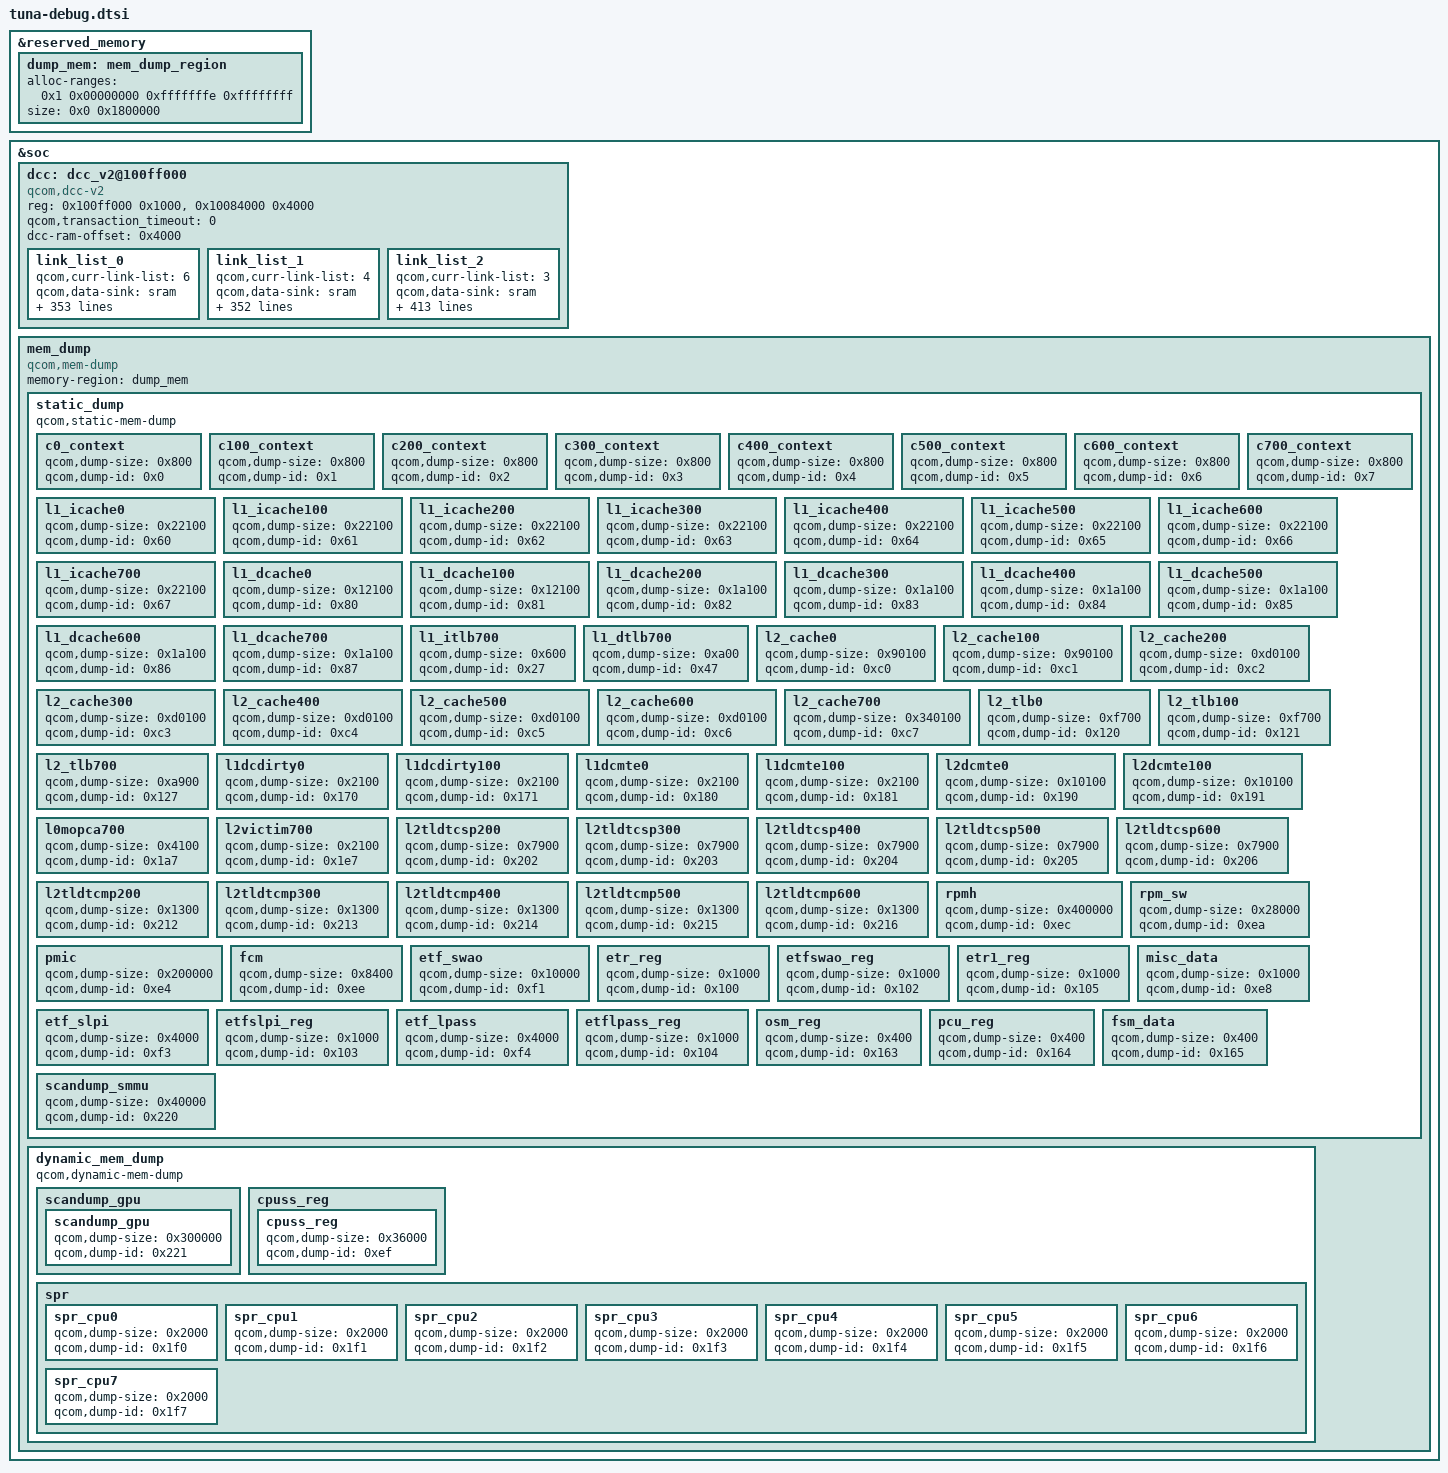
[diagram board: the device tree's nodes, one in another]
// SPDX-License-Identifier: BSD-3-Clause
/*
 * Copyright (c) 2023-2025 Qualcomm Innovation Center, Inc. All rights reserved.
 */

#include <dt-bindings/soc/qcom,dcc_v2.h>

&reserved_memory {
	#address-cells = <2>;
	#size-cells = <2>;
	ranges;

	dump_mem: mem_dump_region {
		alloc-ranges = <0x1 0x00000000 0xfffffffe 0xffffffff>;
		size = <0x0 0x1800000>;
	};
};

&soc {
	dcc: dcc_v2@100ff000 {
		compatible = "qcom,dcc-v2";
		reg = <0x100ff000 0x1000>,
		      <0x10084000 0x4000>;

		qcom,transaction_timeout = <0>;

		reg-names = "dcc-base", "dcc-ram-base";
		dcc-ram-offset = <0x4000>;

		link_list_0 {
			qcom,curr-link-list = <6>;
			qcom,data-sink = "sram";
			qcom,ap-qad-override;
			qcom,link-list = <DCC_READ 0x17421000 2 0>,
				<DCC_READ 0x1740003c 1 0>,
				<DCC_READ 0x17600238 1 0>,
				<DCC_READ 0x17600240 11 0>,
				<DCC_READ 0x17600530 1 0>,
				<DCC_READ 0x1760051c 1 0>,
				<DCC_READ 0x17600524 1 0>,
				<DCC_READ 0x1760052c 1 0>,
				<DCC_READ 0x17600518 1 0>,
				<DCC_READ 0x17600520 1 0>,
				<DCC_READ 0x17600528 1 0>,
				<DCC_READ 0x17600404 3 0>,
				<DCC_READ 0x1760041c 3 0>,
				<DCC_READ 0x17600434 1 0>,
				<DCC_READ 0x1760043c 1 0>,
				<DCC_READ 0x17600440 1 0>,
				<DCC_READ 0x17400438 1 0>,
				<DCC_READ 0x17600044 1 0>,
				<DCC_READ 0x17600500 1 0>,
				<DCC_READ 0x17600504 5 0>,
				<DCC_READ 0x17900908 1 0>,
				<DCC_READ 0x17900c18 1 0>,
				<DCC_READ 0x17901908 1 0>,
				<DCC_READ 0x17901c18 1 0>,
				<DCC_READ 0x17902908 1 0>,
				<DCC_READ 0x17902c18 1 0>,
				<DCC_READ 0x17b90810 1 0>,
				<DCC_READ 0x17b90c50 1 0>,
				<DCC_READ 0x17b90814 1 0>,
				<DCC_READ 0x17b90c54 1 0>,
				<DCC_READ 0x17b90818 1 0>,
				<DCC_READ 0x17b90c58 1 0>,
				<DCC_READ 0x17b93a04 2 0>,
				<DCC_READ 0x17b94810 1 0>,
				<DCC_READ 0x17b94814 1 0>,
				<DCC_READ 0x17b94818 1 0>,
				<DCC_READ 0x17b97a04 1 0>,
				<DCC_READ 0x17ba0810 1 0>,
				<DCC_READ 0x17ba0c50 1 0>,
				<DCC_READ 0x17ba0814 1 0>,
				<DCC_READ 0x17ba0c54 1 0>,
				<DCC_READ 0x17ba0818 1 0>,
				<DCC_READ 0x17ba0c58 1 0>,
				<DCC_READ 0x17ba3a04 2 0>,
				<DCC_READ 0x17b93000 80 0>,
				<DCC_READ 0x17b97000 40 0>,
				<DCC_READ 0x17ba3000 80 0>,
				<DCC_READ 0x0c201244 1 0>,
				<DCC_READ 0x0c202244 1 0>,
				<DCC_READ 0x17b02000 1 0>,
				<DCC_READ 0x17b00000 1 0>,
				<DCC_READ 0x17d98024 1 0>,
				<DCC_READ 0x13822000 1 0>,
				<DCC_READ 0x221c20a4 1 0>,
				<DCC_READ 0x01fc8000 1 0>,
				<DCC_READ 0x17400038 1 0>,
				<DCC_READ 0x17d91020 1 0>,
				<DCC_READ 0x17d92020 1 0>,
				<DCC_READ 0x17d93020 1 0>,
				<DCC_READ 0x17d94020 1 0>,
				<DCC_READ 0x17d90020 1 0>,
				<DCC_READ 0x17d9134c 1 0>,
				<DCC_READ 0x17d9234c 1 0>,
				<DCC_READ 0x17d9334c 1 0>,
				<DCC_READ 0x17d9434c 1 0>,
				<DCC_READ 0x17d9034c 1 0>,
				<DCC_READ 0x17d91300 1 0>,
				<DCC_READ 0x17d92300 1 0>,
				<DCC_READ 0x17d93300 1 0>,
				<DCC_READ 0x17d94300 1 0>,
				<DCC_READ 0x17d90300 1 0>,
				<DCC_READ 0x24100008 1 >,
				<DCC_READ 0x24100010 1 >,
				<DCC_READ 0x24100018 1 >,
				<DCC_READ 0x24100020 6 0>,
				<DCC_READ 0x24102008 1 >,
				<DCC_LOOP 0x2 0 0>,
				<DCC_READ 0x24102010 2 0>,
				<DCC_LOOP 0x1 0 0>,
				<DCC_READ 0x24102018 1 0>,
				<DCC_READ 0x24102080 3 0>,
				<DCC_LOOP 0x3 0 0>,
				<DCC_READ 0x24102090 2 0>,
				<DCC_LOOP 0x1 0 0>,
				<DCC_READ 0x24102098 1 0>,
				<DCC_READ 0x24131010 1 >,
				<DCC_READ 0x24133010 1 >,
				<DCC_READ 0x24135010 1 >,
				<DCC_READ 0x24137010 1 >,
				<DCC_READ 0x24138010 1 >,
				<DCC_READ 0x24180008 1 >,
				<DCC_READ 0x24180010 1 >,
				<DCC_READ 0x24180018 1 >,
				<DCC_READ 0x24180020 6 0>,
				<DCC_READ 0x24182000 3 0>,
				<DCC_LOOP 0x2 0 0>,
				<DCC_READ 0x24182010 2 0>,
				<DCC_LOOP 0x1 0 0>,
				<DCC_READ 0x24182018 1 0>,
				<DCC_READ 0x24182080 3 0>,
				<DCC_LOOP 0x3 0 0>,
				<DCC_READ 0x24182090 2 0>,
				<DCC_LOOP 0x1 0 0>,
				<DCC_READ 0x24182098 1 0>,
				<DCC_READ 0x241b1010 1 >,
				<DCC_READ 0x241b3010 1 >,
				<DCC_READ 0x241b5010 1 >,
				<DCC_READ 0x241b7010 1 >,
				<DCC_READ 0x241b8010 1 >,
				<DCC_READ 0x24200008 1 >,
				<DCC_READ 0x24200010 1 >,
				<DCC_READ 0x24200018 1 >,
				<DCC_READ 0x24200020 6 0>,
				<DCC_READ 0x24200408 1 >,
				<DCC_READ 0x24200410 1 >,
				<DCC_READ 0x24200418 1 >,
				<DCC_READ 0x24200420 6 0>,
				<DCC_READ 0x24201040 1 >,
				<DCC_READ 0x24201048 1 >,
				<DCC_READ 0x24204000 3 0>,
				<DCC_LOOP 0x3 0 0>,
				<DCC_READ 0x24204010 2 0>,
				<DCC_LOOP 0x1 0 0>,
				<DCC_READ 0x24204018 1 0>,
				<DCC_READ 0x24204080 3 0>,
				<DCC_LOOP 0x11 0 0>,
				<DCC_READ 0x24204090 2 0>,
				<DCC_LOOP 0x1 0 0>,
				<DCC_READ 0x24204098 1 0>,
				<DCC_READ 0x24209040 4 0>,
				<DCC_READ 0x2423a010 1 >,
				<DCC_READ 0x2423c010 1 >,
				<DCC_READ 0x2423e010 1 >,
				<DCC_READ 0x24240010 1 >,
				<DCC_READ 0x24242010 1 >,
				<DCC_READ 0x24244010 1 >,
				<DCC_READ 0x24246010 1 >,
				<DCC_READ 0x24248010 1 >,
				<DCC_READ 0x2424a010 1 >,
				<DCC_READ 0x2424b010 1 >,
				<DCC_READ 0x2424d010 1 >,
				<DCC_READ 0x24101010 1 >,
				<DCC_WRITE 0x24101028 0x2 0>,
				<DCC_LOOP 0x40 0 0>,
				<DCC_READ 0x24101030 2 0>,
				<DCC_READ 0x24101030 2 0>,
				<DCC_READ 0x24101030 2 0>,
				<DCC_READ 0x24101030 2 0>,
				<DCC_LOOP 0x1 0 0>,
				<DCC_WRITE 0x24101028 0x1 0>,
				<DCC_READ 0x24101038 1 0>,
				<DCC_READ 0x24181010 1 >,
				<DCC_WRITE 0x24181028 0x2 0>,
				<DCC_LOOP 0x40 0 0>,
				<DCC_READ 0x24181030 2 0>,
				<DCC_READ 0x24181030 2 0>,
				<DCC_READ 0x24181030 2 0>,
				<DCC_READ 0x24181030 2 0>,
				<DCC_LOOP 0x1 0 0>,
				<DCC_WRITE 0x24181028 0x1 0>,
				<DCC_READ 0x24181038 1 0>,
				<DCC_READ 0x24203010 1 >,
				<DCC_WRITE 0x24203028 0x2 0>,
				<DCC_LOOP 0x10 0 0>,
				<DCC_READ 0x24203030 2 0>,
				<DCC_READ 0x24203030 2 0>,
				<DCC_READ 0x24203030 2 0>,
				<DCC_READ 0x24203030 2 0>,
				<DCC_LOOP 0x1 0 0>,
				<DCC_WRITE 0x24203028 0x1 0>,
				<DCC_READ 0x24203038 1 0>,
				<DCC_READ 0x24203410 1 >,
				<DCC_WRITE 0x24203428 0x2 0>,
				<DCC_LOOP 0x10 0 0>,
				<DCC_READ 0x24203430 2 0>,
				<DCC_READ 0x24203430 2 0>,
				<DCC_READ 0x24203430 2 0>,
				<DCC_READ 0x24203430 2 0>,
				<DCC_LOOP 0x1 0 0>,
				<DCC_WRITE 0x24203428 0x1 0>,
				<DCC_READ 0x24203438 1 0>,
				<DCC_READ 0x17800010 1 >,
				<DCC_READ 0x17800024 1 >,
				<DCC_READ 0x17800038 6 0>,
				<DCC_READ 0x17800058 4 0>,
				<DCC_READ 0x1780006c 1 >,
				<DCC_READ 0x178000f0 2 0>,
				<DCC_READ 0x17810010 1 >,
				<DCC_READ 0x17810024 1 >,
				<DCC_READ 0x17810038 6 0>,
				<DCC_READ 0x17810058 4 0>,
				<DCC_READ 0x1781006c 1 >,
				<DCC_READ 0x178100f0 2 0>,
				<DCC_READ 0x17820010 1 >,
				<DCC_READ 0x17820024 1 >,
				<DCC_READ 0x17820038 6 0>,
				<DCC_READ 0x17820058 4 0>,
				<DCC_READ 0x178200f0 2 0>,
				<DCC_READ 0x17830010 1 >,
				<DCC_READ 0x17830024 1 >,
				<DCC_READ 0x17830038 6 0>,
				<DCC_READ 0x17830058 4 0>,
				<DCC_READ 0x178300f0 2 0>,
				<DCC_READ 0x17840010 1 >,
				<DCC_READ 0x17840024 1 >,
				<DCC_READ 0x17840038 6 0>,
				<DCC_READ 0x17840058 4 0>,
				<DCC_READ 0x178400f0 2 0>,
				<DCC_READ 0x17850010 1 >,
				<DCC_READ 0x17850024 1 >,
				<DCC_READ 0x17850038 6 0>,
				<DCC_READ 0x17850058 4 0>,
				<DCC_READ 0x178500f0 2 0>,
				<DCC_READ 0x17860010 1 >,
				<DCC_READ 0x17860024 1 >,
				<DCC_READ 0x17860038 6 0>,
				<DCC_READ 0x17860058 4 0>,
				<DCC_READ 0x178600f0 2 0>,
				<DCC_READ 0x17870010 1 >,
				<DCC_READ 0x17870024 1 >,
				<DCC_READ 0x17870038 6 0>,
				<DCC_READ 0x17870058 4 0>,
				<DCC_READ 0x178700f0 2 0>,
				<DCC_READ 0x178a0010 1 >,
				<DCC_READ 0x178a0024 1 >,
				<DCC_READ 0x178a0038 6 0>,
				<DCC_READ 0x178a006c 5 0>,
				<DCC_READ 0x178a0084 1 >,
				<DCC_READ 0x178a00f4 5 0>,
				<DCC_READ 0x178a0118 9 0>,
				<DCC_READ 0x178a0158 5 0>,
				<DCC_READ 0x178a0170 2 0>,
				<DCC_READ 0x178a0188 5 0>,
				<DCC_READ 0x178a01ac 6 0>,
				<DCC_READ 0x178a01c8 1 >,
				<DCC_READ 0x178a0290 1 >,
				<DCC_READ 0x178a0204 1 >,
				<DCC_READ 0x178a0244 1 >,
				<DCC_READ 0x17e30000 1 >,
				<DCC_READ 0x17e30008 1 >,
				<DCC_READ 0x17e30010 1 >,
				<DCC_READ 0x17e80000 1 >,
				<DCC_READ 0x17e80008 1 >,
				<DCC_READ 0x17e80010 1 >,
				<DCC_READ 0x17f80000 1 >,
				<DCC_READ 0x17f80008 1 >,
				<DCC_READ 0x17f80010 1 >,
				<DCC_READ 0x18080000 1 >,
				<DCC_READ 0x18080008 1 >,
				<DCC_READ 0x18080010 1 >,
				<DCC_READ 0x18180000 1 >,
				<DCC_READ 0x18180008 1 >,
				<DCC_READ 0x18180010 1 >,
				<DCC_READ 0x18280000 1 >,
				<DCC_READ 0x18280008 1 >,
				<DCC_READ 0x18280010 1 >,
				<DCC_READ 0x18380000 1 >,
				<DCC_READ 0x18380008 1 >,
				<DCC_READ 0x18380010 1 >,
				<DCC_READ 0x18480000 1 >,
				<DCC_READ 0x18480008 1 >,
				<DCC_READ 0x18480010 1 >,
				<DCC_READ 0x18580000 1 >,
				<DCC_READ 0x18580008 1 >,
				<DCC_READ 0x18580010 1 >,
				<DCC_READ 0x17d10200 320 0>,
				<DCC_READ 0x17a00010 1 >,
				<DCC_READ 0x17a00030 1 >,
				<DCC_READ 0x17a00038 1 >,
				<DCC_READ 0x17a00040 1 >,
				<DCC_READ 0x17a00048 1 >,
				<DCC_READ 0x17a00400 1 >,
				<DCC_READ 0x17a10010 1 >,
				<DCC_READ 0x17a10030 1 >,
				<DCC_READ 0x17a10038 1 >,
				<DCC_READ 0x17a10040 1 >,
				<DCC_READ 0x17a10400 1 >,
				<DCC_READ 0x17a20010 1 >,
				<DCC_READ 0x17a20030 1 >,
				<DCC_READ 0x17a20038 1 >,
				<DCC_READ 0x17a20040 1 >,
				<DCC_READ 0x17a20400 1 >,
				<DCC_READ 0x17a30010 1 >,
				<DCC_READ 0x17a30030 1 >,
				<DCC_READ 0x17a30038 1 >,
				<DCC_READ 0x17a30040 1 >,
				<DCC_READ 0x17a30400 1 >,
				<DCC_READ 0x17a10d3c 1 >,
				<DCC_READ 0x17a10d54 1 >,
				<DCC_READ 0x17a10d6c 1 >,
				<DCC_READ 0x17a10d84 1 >,
				<DCC_READ 0x17a10d9c 1 >,
				<DCC_READ 0x17a10db4 1 >,
				<DCC_READ 0x17a10dcc 1 >,
				<DCC_READ 0x17a10de4 1 >,
				<DCC_READ 0x17a10dfc 1 >,
				<DCC_READ 0x17a10e14 1 >,
				<DCC_READ 0x17a10e2c 1 >,
				<DCC_READ 0x17a10e44 1 >,
				<DCC_READ 0x17a10e5c 1 >,
				<DCC_READ 0x17a10e74 1 >,
				<DCC_READ 0x17a10e8c 1 >,
				<DCC_READ 0x17a10ea4 1 >,
				<DCC_READ 0x17a10fdc 1 >,
				<DCC_READ 0x17a10ff4 1 >,
				<DCC_READ 0x17a1100c 1 >,
				<DCC_READ 0x17a11024 1 >,
				<DCC_READ 0x17a1103c 1 >,
				<DCC_READ 0x17a11054 1 >,
				<DCC_READ 0x17a1106c 1 >,
				<DCC_READ 0x17a11084 1 >,
				<DCC_READ 0x17a1109c 1 >,
				<DCC_READ 0x17a110b4 1 >,
				<DCC_READ 0x17a110cc 1 >,
				<DCC_READ 0x17a110e4 1 >,
				<DCC_READ 0x17a110fc 1 >,
				<DCC_READ 0x17a11114 1 >,
				<DCC_READ 0x17a1112c 1 >,
				<DCC_READ 0x17a11144 1 >,
				<DCC_READ 0x17a1127c 1 >,
				<DCC_READ 0x17a11294 1 >,
				<DCC_READ 0x17a112ac 1 >,
				<DCC_READ 0x17a112c4 1 >,
				<DCC_READ 0x17a112dc 1 >,
				<DCC_READ 0x17a112f4 1 >,
				<DCC_READ 0x17a1130c 1 >,
				<DCC_READ 0x17a11324 1 >,
				<DCC_READ 0x17a1133c 1 >,
				<DCC_READ 0x17a11354 1 >,
				<DCC_READ 0x17a1136c 1 >,
				<DCC_READ 0x17a11384 1 >,
				<DCC_READ 0x17a1139c 1 >,
				<DCC_READ 0x17a113b4 1 >,
				<DCC_READ 0x17a113cc 1 >,
				<DCC_READ 0x17a113e4 1 >,
				<DCC_READ 0x17a1151c 1 >,
				<DCC_READ 0x17a11534 1 >,
				<DCC_READ 0x17a1154c 1 >,
				<DCC_READ 0x17a11564 1 >,
				<DCC_READ 0x17a1157c 1 >,
				<DCC_READ 0x17a11594 1 >,
				<DCC_READ 0x17a115ac 1 >,
				<DCC_READ 0x17a115c4 1 >,
				<DCC_READ 0x17a115dc 1 >,
				<DCC_READ 0x17a115f4 1 >,
				<DCC_READ 0x17a1160c 1 >,
				<DCC_READ 0x17a11624 1 >,
				<DCC_READ 0x17a1163c 1 >,
				<DCC_READ 0x17a11654 1 >,
				<DCC_READ 0x17a1166c 1 >,
				<DCC_READ 0x17a11684 1 >,
				<DCC_READ 0xc234004 5 0>,
				<DCC_LOOP 0x5 0 0>,
				<DCC_READ 0x17410000 6 0>,
				<DCC_READ 0x17411000 6 0>,
				<DCC_LOOP 0x1 0 0>,
				<DCC_READ 0x4080304 1 >,
				<DCC_READ 0x408030c 1 >,
				<DCC_READ 0x4082028 1 >,
				<DCC_READ 0x4140208 3 0>,
				<DCC_READ 0x4140228 3 0>,
				<DCC_READ 0x4140248 3 0>,
				<DCC_READ 0x4140268 3 0>,
				<DCC_READ 0x4140268 3 0>,
				<DCC_READ 0x4140288 3 0>,
				<DCC_READ 0x41402a8 3 0>,
				<DCC_READ 0x4140400 3 0>,
				<DCC_READ 0x4200208 3 0>,
				<DCC_READ 0x4200228 3 0>,
				<DCC_READ 0x4200248 3 0>,
				<DCC_READ 0x4200268 3 0>,
				<DCC_READ 0x4200288 3 0>,
				<DCC_READ 0x42002a8 3 0>,
				<DCC_READ 0x4200400 3 0>,
				<DCC_READ 0x17421000 2 0>;
		};

		link_list_1 {
			qcom,curr-link-list = <4>;
			qcom,data-sink = "sram";
			qcom,ap-qad-override;
			qcom,link-list = <DCC_READ 0x17421000 2 0>,
				<DCC_READ 0x1780000 3 0>,
				<DCC_READ 0x1780010 1 >,
				<DCC_READ 0x1780018 1 >,
				<DCC_READ 0x1780020 8 0>,
				<DCC_READ 0x1780240 1 >,
				<DCC_READ 0x1780248 1 >,
				<DCC_READ 0x1782200 3 0>,
				<DCC_LOOP 0x7 0 0>,
				<DCC_READ 0x1782210 2 0>,
				<DCC_LOOP 0x1 0 0>,
				<DCC_READ 0x1782218 1 0>,
				<DCC_READ 0x1782300 3 0>,
				<DCC_LOOP 0x8 0 0>,
				<DCC_READ 0x1782310 2 0>,
				<DCC_LOOP 0x1 0 0>,
				<DCC_READ 0x1782318 1 0>,
				<DCC_READ 0x17a5010 1 >,
				<DCC_READ 0x17a6010 1 >,
				<DCC_READ 0x17a7010 1 >,
				<DCC_READ 0x17a8010 1 >,
				<DCC_READ 0x17a9010 1 >,
				<DCC_READ 0x17aa010 1 >,
				<DCC_READ 0x17ab010 1 >,
				<DCC_READ 0x17ac010 1 >,
				<DCC_READ 0x17ad010 1 >,
				<DCC_READ 0x17c0000 3 0>,
				<DCC_READ 0x17c0010 1 >,
				<DCC_READ 0x17c0018 1 >,
				<DCC_READ 0x17c0020 8 0>,
				<DCC_READ 0x17c0240 1 >,
				<DCC_READ 0x17c0248 1 >,
				<DCC_READ 0x17c2000 3 0>,
				<DCC_LOOP 0x6 0 0>,
				<DCC_READ 0x17c2010 2 0>,
				<DCC_LOOP 0x1 0 0>,
				<DCC_READ 0x17c2018 1 0>,
				<DCC_READ 0x17c2100 3 0>,
				<DCC_LOOP 0x11 0 0>,
				<DCC_READ 0x17c2110 2 0>,
				<DCC_LOOP 0x1 0 0>,
				<DCC_READ 0x17c2118 1 0>,
				<DCC_READ 0x17e4010 1 >,
				<DCC_READ 0x17e5010 1 >,
				<DCC_READ 0x17e6010 1 >,
				<DCC_READ 0x17e7010 1 >,
				<DCC_READ 0x17610008 1 >,
				<DCC_READ 0x17610010 1 >,
				<DCC_READ 0x17610018 1 >,
				<DCC_READ 0x17610020 8 0>,
				<DCC_READ 0x17610240 1 >,
				<DCC_READ 0x17610248 1 >,
				<DCC_READ 0x17612008 1 >,
				<DCC_LOOP 0x6 0 0>,
				<DCC_READ 0x17612010 2 0>,
				<DCC_LOOP 0x1 0 0>,
				<DCC_READ 0x17612018 1 0>,
				<DCC_READ 0x1680010 1 >,
				<DCC_READ 0x1680018 1 >,
				<DCC_READ 0x1680020 8 0>,
				<DCC_READ 0x1681040 1 >,
				<DCC_READ 0x1681048 1 >,
				<DCC_READ 0x1682008 1 >,
				<DCC_LOOP 0x6 0 0>,
				<DCC_READ 0x1682010 2 0>,
				<DCC_LOOP 0x1 0 0>,
				<DCC_READ 0x1682018 1 0>,
				<DCC_READ 0x1690010 1 >,
				<DCC_READ 0x1698010 1 >,
				<DCC_READ 0x1699010 1 >,
				<DCC_READ 0x169c010 1 >,
				<DCC_READ 0x169d010 1 >,
				<DCC_READ 0x16e0000 3 0>,
				<DCC_READ 0x16e0010 1 >,
				<DCC_READ 0x16e0018 1 >,
				<DCC_READ 0x16e0020 8 0>,
				<DCC_READ 0x16e0240 1 >,
				<DCC_READ 0x16e0248 1 >,
				<DCC_READ 0x16e1000 3 0>,
				<DCC_LOOP 0x2 0 0>,
				<DCC_READ 0x16e1010 2 0>,
				<DCC_LOOP 0x1 0 0>,
				<DCC_READ 0x16e1018 1 0>,
				<DCC_READ 0x16e1080 3 0>,
				<DCC_LOOP 0x3 0 0>,
				<DCC_READ 0x16e1090 2 0>,
				<DCC_LOOP 0x1 0 0>,
				<DCC_READ 0x16e1098 1 0>,
				<DCC_READ 0x16e1100 3 0>,
				<DCC_LOOP 0x7 0 0>,
				<DCC_READ 0x16e1110 2 0>,
				<DCC_LOOP 0x1 0 0>,
				<DCC_READ 0x16e1118 1 0>,
				<DCC_READ 0x16e1180 3 0>,
				<DCC_LOOP 0x3 0 0>,
				<DCC_READ 0x16e1190 2 0>,
				<DCC_LOOP 0x1 0 0>,
				<DCC_READ 0x16e1198 1 0>,
				<DCC_READ 0x16e2200 3 0>,
				<DCC_LOOP 0x2 0 0>,
				<DCC_READ 0x16e2210 2 0>,
				<DCC_LOOP 0x1 0 0>,
				<DCC_READ 0x16e2218 1 0>,
				<DCC_READ 0x16ec010 1 >,
				<DCC_READ 0x16ed010 1 >,
				<DCC_READ 0x16ef010 1 >,
				<DCC_READ 0x16f0010 1 >,
				<DCC_READ 0x16f1010 1 >,
				<DCC_READ 0x16c0000 3 0>,
				<DCC_READ 0x16c0010 1 >,
				<DCC_READ 0x16c0018 1 >,
				<DCC_READ 0x16c0020 8 0>,
				<DCC_READ 0x16c0240 1 >,
				<DCC_READ 0x16c0248 1 >,
				<DCC_READ 0x16c2000 3 0>,
				<DCC_LOOP 0x4 0 0>,
				<DCC_READ 0x16c2010 2 0>,
				<DCC_LOOP 0x1 0 0>,
				<DCC_READ 0x16c2018 1 0>,
				<DCC_READ 0x16c3000 3 0>,
				<DCC_LOOP 0x4 0 0>,
				<DCC_READ 0x16c3010 2 0>,
				<DCC_LOOP 0x1 0 0>,
				<DCC_READ 0x16c3018 1 0>,
				<DCC_READ 0x16cb010 1 >,
				<DCC_READ 0x1700000 3 0>,
				<DCC_READ 0x1700010 1 >,
				<DCC_READ 0x1700018 1 >,
				<DCC_READ 0x1700020 8 0>,
				<DCC_READ 0x1700240 1 >,
				<DCC_READ 0x1700248 1 >,
				<DCC_READ 0x1702000 3 0>,
				<DCC_LOOP 0x5 0 0>,
				<DCC_READ 0x1702010 2 0>,
				<DCC_LOOP 0x1 0 0>,
				<DCC_READ 0x1702018 1 0>,
				<DCC_READ 0x1702200 3 0>,
				<DCC_LOOP 0x2 0 0>,
				<DCC_READ 0x1702210 2 0>,
				<DCC_LOOP 0x1 0 0>,
				<DCC_READ 0x1702218 1 0>,
				<DCC_READ 0x1714010 1 >,
				<DCC_READ 0x1715010 1 >,
				<DCC_READ 0x1716010 1 >,
				<DCC_READ 0x1717010 1 >,
				<DCC_READ 0x1718010 1 >,
				<DCC_READ 0x171a010 1 >,
				<DCC_READ 0x1500010 1 >,
				<DCC_READ 0x1500018 1 >,
				<DCC_READ 0x1500020 8 0>,
				<DCC_READ 0x1500240 1 >,
				<DCC_READ 0x1500248 1 >,
				<DCC_READ 0x1500440 1 >,
				<DCC_READ 0x1500448 1 >,
				<DCC_READ 0x1502008 1 >,
				<DCC_LOOP 0xb 0 0>,
				<DCC_READ 0x1502010 2 0>,
				<DCC_LOOP 0x1 0 0>,
				<DCC_READ 0x1502018 1 0>,
				<DCC_READ 0x1600010 1 >,
				<DCC_READ 0x1600018 1 >,
				<DCC_READ 0x1600020 8 0>,
				<DCC_READ 0x1600240 5 0>,
				<DCC_READ 0x1600258 1 >,
				<DCC_READ 0x1602008 1 >,
				<DCC_LOOP 0x7 0 0>,
				<DCC_READ 0x1602010 2 0>,
				<DCC_LOOP 0x1 0 0>,
				<DCC_READ 0x1602018 1 0>,
				<DCC_READ 0x1602080 3 0>,
				<DCC_LOOP 0x2 0 0>,
				<DCC_READ 0x1602090 2 0>,
				<DCC_LOOP 0x1 0 0>,
				<DCC_READ 0x1602098 1 0>,
				<DCC_READ 0x1602100 3 0>,
				<DCC_LOOP 0x3 0 0>,
				<DCC_READ 0x1602110 2 0>,
				<DCC_LOOP 0x1 0 0>,
				<DCC_READ 0x1602118 1 0>,
				<DCC_READ 0x1602180 3 0>,
				<DCC_LOOP 0x3 0 0>,
				<DCC_READ 0x1602190 2 0>,
				<DCC_LOOP 0x1 0 0>,
				<DCC_READ 0x1602198 1 0>,
				<DCC_READ 0x1602200 3 0>,
				<DCC_LOOP 0x3 0 0>,
				<DCC_READ 0x1602210 2 0>,
				<DCC_LOOP 0x1 0 0>,
				<DCC_READ 0x1602218 1 0>,
				<DCC_READ 0x1602280 3 0>,
				<DCC_LOOP 0x3 0 0>,
				<DCC_READ 0x1602290 2 0>,
				<DCC_LOOP 0x1 0 0>,
				<DCC_READ 0x1602298 1 0>,
				<DCC_READ 0x1602300 3 0>,
				<DCC_LOOP 0x2 0 0>,
				<DCC_READ 0x1602310 2 0>,
				<DCC_LOOP 0x1 0 0>,
				<DCC_READ 0x1602318 1 0>,
				<DCC_READ 0x1602380 3 0>,
				<DCC_LOOP 0x3 0 0>,
				<DCC_READ 0x1602390 2 0>,
				<DCC_LOOP 0x1 0 0>,
				<DCC_READ 0x1602398 1 0>,
				<DCC_READ 0x1602400 3 0>,
				<DCC_LOOP 0x2 0 0>,
				<DCC_READ 0x1602410 2 0>,
				<DCC_LOOP 0x1 0 0>,
				<DCC_READ 0x1602418 1 0>,
				<DCC_READ 0xb281024 1 0>,
				<DCC_READ 0xbde1034 1 0>,
				<DCC_READ 0xb201020 2 0>,
				<DCC_READ 0xb211020 2 0>,
				<DCC_READ 0xb221020 2 0>,
				<DCC_READ 0xb231020 2 0>,
				<DCC_READ 0xb204520 1 0>,
				<DCC_READ 0xb200000 1 0>,
				<DCC_READ 0xb210000 1 0>,
				<DCC_READ 0xb220000 1 0>,
				<DCC_READ 0xb230000 1 0>,
				<DCC_READ 0x8a00304 1 >,
				<DCC_READ 0x8a0030c 1 >,
				<DCC_READ 0x8a02028 1 >,
				<DCC_READ 0x8ac0208  3>,
				<DCC_READ 0x8ac0228 3 0>,
				<DCC_READ 0x8ac0248 3 0>,
				<DCC_READ 0x8ac0268 3 0>,
				<DCC_READ 0x8ac0288 3 0>,
				<DCC_READ 0x8ac02ac 2 0>,
				<DCC_READ 0x8ac02a8 1 >,
				<DCC_READ 0x8ac0400 3 0>,
				<DCC_READ 0x17120000 1 >,
				<DCC_READ 0x17120008 1 >,
				<DCC_READ 0x17120010 1 >,
				<DCC_READ 0x17120018 1 >,
				<DCC_READ 0x17120020 1 >,
				<DCC_READ 0x17120028 1 >,
				<DCC_READ 0x17120040 1 >,
				<DCC_READ 0x17120048 1 >,
				<DCC_READ 0x17120050 1 >,
				<DCC_READ 0x17120058 1 >,
				<DCC_READ 0x17120060 1 >,
				<DCC_READ 0x17120068 1 >,
				<DCC_READ 0x17120080 1 >,
				<DCC_READ 0x17120088 1 >,
				<DCC_READ 0x17120090 1 >,
				<DCC_READ 0x17120098 1 >,
				<DCC_READ 0x171200a0 1 >,
				<DCC_READ 0x171200a8 1 >,
				<DCC_READ 0x171200c0 1 >,
				<DCC_READ 0x171200c8 1 >,
				<DCC_READ 0x171200d0 1 >,
				<DCC_READ 0x171200d8 1 >,
				<DCC_READ 0x171200e0 1 >,
				<DCC_READ 0x171200e8 1 >,
				<DCC_READ 0x17120100 1 >,
				<DCC_READ 0x17120108 1 >,
				<DCC_READ 0x17120110 1 >,
				<DCC_READ 0x17120118 1 >,
				<DCC_READ 0x17120120 1 >,
				<DCC_READ 0x17120128 1 >,
				<DCC_READ 0x17120140 1 >,
				<DCC_READ 0x17120148 1 >,
				<DCC_READ 0x17120150 1 >,
				<DCC_READ 0x17120158 1 >,
				<DCC_READ 0x17120160 1 >,
				<DCC_READ 0x17120168 1 >,
				<DCC_READ 0x17120180 1 >,
				<DCC_READ 0x17120188 1 >,
				<DCC_READ 0x17120190 1 >,
				<DCC_READ 0x17120198 1 >,
				<DCC_READ 0x171201a0 1 >,
				<DCC_READ 0x171201a8 1 >,
				<DCC_READ 0x171201c0 1 >,
				<DCC_READ 0x171201c8 1 >,
				<DCC_READ 0x171201d0 1 >,
				<DCC_READ 0x171201d8 1 >,
				<DCC_READ 0x171201e0 1 >,
				<DCC_READ 0x171201e8 1 >,
				<DCC_READ 0x17120200 1 >,
				<DCC_READ 0x17120208 1 >,
				<DCC_READ 0x17120210 1 >,
				<DCC_READ 0x17120218 1 >,
				<DCC_READ 0x17120220 1 >,
				<DCC_READ 0x17120228 1 >,
				<DCC_READ 0x17120240 1 >,
				<DCC_READ 0x17120248 1 >,
				<DCC_READ 0x17120250 1 >,
				<DCC_READ 0x17120258 1 >,
				<DCC_READ 0x17120260 1 >,
				<DCC_READ 0x17120268 1 >,
				<DCC_READ 0x17120280 1 >,
				<DCC_READ 0x17120288 1 >,
				<DCC_READ 0x17120290 1 >,
				<DCC_READ 0x17120298 1 >,
				<DCC_READ 0x171202a0 1 >,
				<DCC_READ 0x171202a8 1 >,
				<DCC_READ 0x171202c0 1 >,
				<DCC_READ 0x171202c8 1 >,
				<DCC_READ 0x171202d0 1 >,
				<DCC_READ 0x171202d8 1 >,
				<DCC_READ 0x171202e0 1 >,
				<DCC_READ 0x171202e8 1 >,
				<DCC_READ 0x17120300 1 >,
				<DCC_READ 0x17120308 1 >,
				<DCC_READ 0x17120310 1 >,
				<DCC_READ 0x17120318 1 >,
				<DCC_READ 0x17120320 1 >,
				<DCC_READ 0x17120328 1 >,
				<DCC_READ 0x17120340 1 >,
				<DCC_READ 0x17120348 1 >,
				<DCC_READ 0x17120350 1 >,
				<DCC_READ 0x17120358 1 >,
				<DCC_READ 0x17120360 1 >,
				<DCC_READ 0x17120368 1 >,
				<DCC_READ 0x17120380 1 >,
				<DCC_READ 0x17120388 1 >,
				<DCC_READ 0x17120390 1 >,
				<DCC_READ 0x17120398 1 >,
				<DCC_READ 0x171203a0 1 >,
				<DCC_READ 0x171203a8 1 >,
				<DCC_READ 0x171203c0 1 >,
				<DCC_READ 0x171203c8 1 >,
				<DCC_READ 0x171203d0 1 >,
				<DCC_READ 0x171203d8 1 >,
				<DCC_READ 0x171203e0 1 >,
				<DCC_READ 0x171203e8 1 >,
				<DCC_READ 0x17120400 1 >,
				<DCC_READ 0x17120408 1 >,
				<DCC_READ 0x17120410 1 >,
				<DCC_READ 0x17120418 1 >,
				<DCC_READ 0x17120420 1 >,
				<DCC_READ 0x17120428 1 >,
				<DCC_READ 0x17120440 1 >,
				<DCC_READ 0x17120448 1 >,
				<DCC_READ 0x17120450 1 >,
				<DCC_READ 0x17120458 1 >,
				<DCC_READ 0x17120460 1 >,
				<DCC_READ 0x17120468 1 >,
				<DCC_READ 0x17120480 1 >,
				<DCC_READ 0x17120488 1 >,
				<DCC_READ 0x17120490 1 >,
				<DCC_READ 0x17120498 1 >,
				<DCC_READ 0x171204a0 1 >,
				<DCC_READ 0x171204a8 1 >,
				<DCC_READ 0x171204c0 1 >,
				<DCC_READ 0x171204c8 1 >,
				<DCC_READ 0x171204d0 1 >,
				<DCC_READ 0x171204d8 1 >,
				<DCC_READ 0x171204e0 1 >,
				<DCC_READ 0x171204e8 1 >,
				<DCC_READ 0x17120500 1 >,
				<DCC_READ 0x17120508 1 >,
				<DCC_READ 0x17120510 1 >,
				<DCC_READ 0x17120518 1 >,
				<DCC_READ 0x17120520 1 >,
				<DCC_READ 0x17120528 1 >,
				<DCC_READ 0x17120540 1 >,
				<DCC_READ 0x17120548 1 >,
				<DCC_READ 0x17120550 1 >,
				<DCC_READ 0x17120558 1 >,
				<DCC_READ 0x17120560 1 >,
				<DCC_READ 0x17120568 1 >,
				<DCC_READ 0x17120580 1 >,
				<DCC_READ 0x17120588 1 >,
				<DCC_READ 0x17120590 1 >,
				<DCC_READ 0x17120598 1 >,
				<DCC_READ 0x171205a0 1 >,
				<DCC_READ 0x171205a8 1 >,
				<DCC_READ 0x171205c0 1 >,
				<DCC_READ 0x171205c8 1 >,
				<DCC_READ 0x171205d0 1 >,
				<DCC_READ 0x171205d8 1 >,
				<DCC_READ 0x171205e0 1 >,
				<DCC_READ 0x171205e8 1 >,
				<DCC_READ 0x17120600 1 >,
				<DCC_READ 0x17120608 1 >,
				<DCC_READ 0x17120610 1 >,
				<DCC_READ 0x17120618 1 >,
				<DCC_READ 0x17120620 1 >,
				<DCC_READ 0x17120628 1 >,
				<DCC_READ 0x17120640 1 >,
				<DCC_READ 0x17120648 1 >,
				<DCC_READ 0x17120650 1 >,
				<DCC_READ 0x17120658 1 >,
				<DCC_READ 0x17120660 1 >,
				<DCC_READ 0x17120668 1 >,
				<DCC_READ 0x17120680 1 >,
				<DCC_READ 0x17120688 1 >,
				<DCC_READ 0x17120690 1 >,
				<DCC_READ 0x17120698 1 >,
				<DCC_READ 0x171206a0 1 >,
				<DCC_READ 0x171206a8 1 >,
				<DCC_READ 0x171206c0 1 >,
				<DCC_READ 0x171206c8 1 >,
				<DCC_READ 0x171206d0 1 >,
				<DCC_READ 0x171206d8 1 >,
				<DCC_READ 0x171206e0 1 >,
				<DCC_READ 0x171206e8 1 >,
				<DCC_READ 0x1712e000 1 >,
				<DCC_READ 0x320a4208 2 0>,
				<DCC_READ 0x320a4228 3 0>,
				<DCC_READ 0x320a4248 3 0>,
				<DCC_READ 0x320a4268 3 0>,
				<DCC_READ 0x320a4288 3 0>,
				<DCC_READ 0x320a42a8 3 0>,
				<DCC_READ 0x320a4400 3 0>,
				<DCC_READ 0x3230030c 1 0>,
				<DCC_READ 0x32302028 1 0>,
				<DCC_READ 0x323c0208 3 0>,
				<DCC_READ 0x323c0228 3 0>,
				<DCC_READ 0x323c0248 3 0>,
				<DCC_READ 0x323c0268 3 0>,
				<DCC_READ 0x323c0288 3 0>,
				<DCC_READ 0x323c02a8 3 0>,
				<DCC_READ 0x323c0400 3 0>,
				<DCC_READ 0x24868100 1 >,
				<DCC_READ 0x24872044 2 >,
				<DCC_READ 0x24872104 1 >,
				<DCC_READ 0x2487204c 1 >,
				<DCC_READ 0x25868100 1 >,
				<DCC_READ 0x25872044 2 >,
				<DCC_READ 0x25872104 1 >,
				<DCC_READ 0x2587204c 1 >,
				<DCC_READ 0x24c68100 1 >,
				<DCC_READ 0x24c72044 2 >,
				<DCC_READ 0x24c72104 1 >,
				<DCC_READ 0x24c7204c 1 >,
				<DCC_READ 0x25c68100 1 >,
				<DCC_READ 0x25c72044 2 >,
				<DCC_READ 0x25c72104 1 >,
				<DCC_READ 0x25c7204c 1 >,
				<DCC_READ 0x17421000 2 0>;
		};

		link_list_2 {
			qcom,curr-link-list = <3>;
			qcom,data-sink = "sram";
			qcom,ap-qad-override;
			qcom,link-list = <DCC_READ 0x17421000 2 0>,
				<DCC_READ 0x0c222004 1 0>,
				<DCC_READ 0x0c228014 1 0>,
				<DCC_READ 0x0c2280e0 1 0>,
				<DCC_READ 0x0c2280ec 1 0>,
				<DCC_READ 0x0c2280a0 16 0>,
				<DCC_READ 0x0c2280e8 1 0>,
				<DCC_READ 0x0c22813c 1 0>,
				<DCC_READ 0x0c223004 1 0>,
				<DCC_READ 0x0c229014 1 0>,
				<DCC_READ 0x0c2290e0 1 0>,
				<DCC_READ 0x0c2290ec 1 0>,
				<DCC_READ 0x0c2290a0 16 0>,
				<DCC_READ 0x0c2290e8 1 0>,
				<DCC_READ 0x0c22913c 1 0>,
				<DCC_READ 0x0c224004 1 0>,
				<DCC_READ 0x0c22a014 1 0>,
				<DCC_READ 0x0c22a0e0 1 0>,
				<DCC_READ 0x0c22a0ec 1 0>,
				<DCC_READ 0x0c22a0a0 16 0>,
				<DCC_READ 0x0c22a0e8 1 0>,
				<DCC_READ 0x0c22a13c 1 0>,
				<DCC_READ 0x0c225004 1 0>,
				<DCC_READ 0x0c22b014 1 0>,
				<DCC_READ 0x0c22b0e0 1 0>,
				<DCC_READ 0x0c22b0ec 1 0>,
				<DCC_READ 0x0c22b0a0 16 0>,
				<DCC_READ 0x0c22b0e8 1 0>,
				<DCC_READ 0x0c22b13c 1 0>,
				<DCC_READ 0xec80010 1 0>,
				<DCC_READ 0xec81000 1 0>,
				<DCC_READ 0xec81010 161 0>,
				<DCC_READ 0xec81050 16 0>,
				<DCC_READ 0xec81090 16 0>,
				<DCC_READ 0xec810d0 16 0>,
				<DCC_READ 0xec81550 1 0>,
				<DCC_READ 0x17b70220 6 0>,
				<DCC_READ 0x17b702a0 6 0>,
				<DCC_READ 0x17b70320 1 0>,
				<DCC_READ 0x17b704e0 16 0>,
				<DCC_READ 0x17b70560 1 0>,
				<DCC_READ 0x17b70580 1 0>,
				<DCC_READ 0x17b70688 1 0>,
				<DCC_READ 0x17b70730  2>,
				<DCC_READ 0x17b70738  2>,
				<DCC_READ 0x17b70740   2>,
				<DCC_READ 0x17b71190  24>,
				<DCC_READ 0x17b71490   16>,
				<DCC_READ 0x17b71510   16>,
				<DCC_READ 0x17b72290   8>,
				<DCC_READ 0x17b74220 6 0>,
				<DCC_READ 0x17b742a0 6 0>,
				<DCC_READ 0x17b74320 1 0>,
				<DCC_READ 0x17b744e0 16 0>,
				<DCC_READ 0x17b74560 1 0>,
				<DCC_READ 0x17b74580 1 0>,
				<DCC_READ 0x17b74688 1 0>,
				<DCC_READ 0x17b74730  2>,
				<DCC_READ 0x17b74738  2>,
				<DCC_READ 0x17b74740   2>,
				<DCC_READ 0x17b75190  24>,
				<DCC_READ 0x17b75490   16>,
				<DCC_READ 0x17b75510   16>,
				<DCC_READ 0x17b76290   8>,
				<DCC_READ 0x17b78220 6 0>,
				<DCC_READ 0x17b782a0 6 0>,
				<DCC_READ 0x17b78320 1 0>,
				<DCC_READ 0x17b784e0 16 0>,
				<DCC_READ 0x17b78560 1 0>,
				<DCC_READ 0x17b78580 1 0>,
				<DCC_READ 0x17b78688 1 0>,
				<DCC_READ 0x17b78730    2 1 0>,
				<DCC_READ 0x17b78738  2>,
				<DCC_READ 0x17b78740   2>,
				<DCC_READ 0x17b79190  24>,
				<DCC_READ 0x17b79490   16>,
				<DCC_READ 0x17b79510  16>,
				<DCC_READ 0x17b7a290   8>,
				<DCC_READ 0x32310220 6 0>,
				<DCC_READ 0x323102a0 6 0>,
				<DCC_READ 0x32310320 1 0>,
				<DCC_READ 0x323104e0 8 0>,
				<DCC_READ 0x32310560 1 0>,
				<DCC_READ 0x32310580 1 0>,
				<DCC_READ 0x32310688 1 0>,
				<DCC_READ 0x32310730  2>,
				<DCC_READ 0x32310738  2>,
				<DCC_READ 0x32310740  2>,
				<DCC_READ 0x32311190  8>,
				<DCC_READ 0x32311490   6>,
				<DCC_READ 0x32311510   6>,
				<DCC_READ 0x32312290   3>,
				<DCC_READ 0x7400010 1 >,
				<DCC_READ 0x7400018 1 >,
				<DCC_READ 0x7400020 8 0>,
				<DCC_READ 0x7402040 1 >,
				<DCC_READ 0x7402048 1 >,
				<DCC_READ 0x7403000 3 0>,
				<DCC_LOOP 0x2 0 0>,
				<DCC_READ 0x7403010 2 0>,
				<DCC_LOOP 0x1 0 0>,
				<DCC_READ 0x7403018 1 0>,
				<DCC_READ 0x7410010 1 >,
				<DCC_READ 0x7410018 1 >,
				<DCC_READ 0x7410020 8 0>,
				<DCC_READ 0x7410240 1 >,
				<DCC_READ 0x7410248 1 >,
				<DCC_READ 0x7412000 3 0>,
				<DCC_LOOP 0x3 0 0>,
				<DCC_READ 0x7412010 2 0>,
				<DCC_LOOP 0x1 0 0>,
				<DCC_READ 0x7412018 1 0>,
				<DCC_READ 0x7420008 1 >,
				<DCC_LOOP 0x3 0 0>,
				<DCC_READ 0x7420010 2 0>,
				<DCC_LOOP 0x1 0 0>,
				<DCC_READ 0x7420018 1 0>,
				<DCC_READ 0x7422040 1 >,
				<DCC_READ 0x7422048 1 >,
				<DCC_READ 0x7425008 1 >,
				<DCC_READ 0x7425010 1 >,
				<DCC_READ 0x7430010 1 >,
				<DCC_READ 0x7430018 1 >,
				<DCC_READ 0x7430020 8 0>,
				<DCC_READ 0x7430240 1 >,
				<DCC_READ 0x7430248 1 >,
				<DCC_READ 0x7432000 3 0>,
				<DCC_LOOP 0xe 0 0>,
				<DCC_READ 0x7432010 2 0>,
				<DCC_LOOP 0x1 0 0>,
				<DCC_READ 0x7432018 1 0>,
				<DCC_READ 0x7446008 1 >,
				<DCC_READ 0x7446010 1 >,
				<DCC_READ 0x7447008 1 >,
				<DCC_READ 0x7447010 1 >,
				<DCC_READ 0x7448008 1 >,
				<DCC_READ 0x7448010 1 >,
				<DCC_READ 0x7449008 1 >,
				<DCC_READ 0x7449010 1 >,
				<DCC_READ 0x744a008 1 >,
				<DCC_READ 0x744a010 1 >,
				<DCC_READ 0x744b008 1 >,
				<DCC_READ 0x744b010 1 >,
				<DCC_READ 0x7460000 3 0>,
				<DCC_LOOP 0x2 0 0>,
				<DCC_READ 0x7460010 2 0>,
				<DCC_LOOP 0x1 0 0>,
				<DCC_READ 0x7460018 1 0>,
				<DCC_READ 0x7462040 1 >,
				<DCC_READ 0x7462048 1 >,
				<DCC_READ 0x74b0010 1 >,
				<DCC_READ 0x74b0018 1 >,
				<DCC_READ 0x74b0020 8 0>,
				<DCC_READ 0x74b0240 1 >,
				<DCC_READ 0x74b0248 1 >,
				<DCC_READ 0x74b1000 3 0>,
				<DCC_LOOP 0x7 0 0>,
				<DCC_READ 0x74b1010 2 0>,
				<DCC_LOOP 0x1 0 0>,
				<DCC_READ 0x74b1018 1 0>,
				<DCC_READ 0x74c1000 3 0>,
				<DCC_LOOP 0x2 0 0>,
				<DCC_READ 0x74c1010 2 0>,
				<DCC_LOOP 0x1 0 0>,
				<DCC_READ 0x74c1018 1 0>,
				<DCC_READ 0x74c7040 1 >,
				<DCC_READ 0x74c7048 1 >,
				<DCC_READ 0x7b6040 1 >,
				<DCC_READ 0x7b6048 1 >,
				<DCC_READ 0x7be000 3 0>,
				<DCC_LOOP 0x4 0 0>,
				<DCC_READ 0x7be010 2 0>,
				<DCC_LOOP 0x1 0 0>,
				<DCC_READ 0x7be018 1 0>,
				<DCC_READ 0x7bf000 3 0>,
				<DCC_LOOP 0x4 0 0>,
				<DCC_READ 0x7bf010 2 0>,
				<DCC_LOOP 0x1 0 0>,
				<DCC_READ 0x7bf018 1 0>,
				<DCC_READ 0x7e40010 1 >,
				<DCC_READ 0x7e40018 1 >,
				<DCC_READ 0x7e40020 8 0>,
				<DCC_READ 0x7e40240 1 >,
				<DCC_READ 0x7e40248 1 >,
				<DCC_READ 0x7e42008 1 >,
				<DCC_LOOP 0x6 0 0>,
				<DCC_READ 0x7e42010 2 0>,
				<DCC_LOOP 0x1 0 0>,
				<DCC_READ 0x7e42018 1 0>,
				<DCC_READ 0x7e4d010 1 >,
				<DCC_READ 0x7e4e010 1 >,
				<DCC_READ 0x320c0008 1 >,
				<DCC_READ 0x320c0010 1 >,
				<DCC_READ 0x320c0018 1 >,
				<DCC_READ 0x320c0020 8 0>,
				<DCC_READ 0x320c0240 1 >,
				<DCC_READ 0x320c0248 1 >,
				<DCC_READ 0x320c1008 1 >,
				<DCC_LOOP 0x5 0 0>,
				<DCC_READ 0x320c1010 2 0>,
				<DCC_LOOP 0x1 0 0>,
				<DCC_READ 0x320c1018 1 0>,
				<DCC_READ 0x320cc010 1 >,
				<DCC_READ 0x320cd010 1 >,
				<DCC_READ 0x320ce010 1 >,
				<DCC_READ 0x7d6040 1 >,
				<DCC_READ 0x7d6048 1 >,
				<DCC_READ 0x7df000 3 0>,
				<DCC_LOOP 0x4 0 0>,
				<DCC_READ 0x7df010 2 0>,
				<DCC_LOOP 0x1 0 0>,
				<DCC_READ 0x7df018 1 0>,
				<DCC_READ 0x7e0000 3 0>,
				<DCC_LOOP 0x7 0 0>,
				<DCC_READ 0x7e0010 2 0>,
				<DCC_LOOP 0x1 0 0>,
				<DCC_READ 0x7e0018 1 0>,
				<DCC_READ 0x110018 10 0>,
				<DCC_READ 0x11c018 10 0>,
				<DCC_READ 0x178030 1 >,
				<DCC_READ 0x178040 1 >,
				<DCC_READ 0x190890 1 >,
				<DCC_READ 0x199014 10 0>,
				<DCC_READ 0x19d014 10 0>,
				<DCC_READ 0x1ad030 4 0>,
				<DCC_READ 0x17100104 29 0>,
				<DCC_READ 0x17100204 29 0>,
				<DCC_READ 0x17100384 29 0>,
				<DCC_READ 0x178a0250 1 0>,
				<DCC_READ 0x178a0254 1 0>,
				<DCC_READ 0x178a025c 1 0>,
				<DCC_READ 0x129000  1 >,
				<DCC_READ 0x12903c  1 >,
				<DCC_READ 0x171004  1 >,
				<DCC_READ 0x17100c  5>,
				<DCC_READ 0x171158  1 >,
				<DCC_READ 0x17b000  1 >,
				<DCC_READ 0x17b03c  1 >,
				<DCC_READ 0x17c000  1 >,
				<DCC_READ 0x17c03c  1 >,
				<DCC_READ 0x17d000  1 >,
				<DCC_READ 0x17d03c  1 >,
				<DCC_READ 0x17e000  1 >,
				<DCC_READ 0x17e03c  1 >,
				<DCC_READ 0x3d00000 1 >,
				<DCC_READ 0x3d00008 1 >,
				<DCC_READ 0x3d00020 6 0>,
				<DCC_READ 0x3d00040 4 0>,
				<DCC_READ 0x3d00054 2 0>,
				<DCC_READ 0x3d00060 1 >,
				<DCC_READ 0x3d00068 1 >,
				<DCC_READ 0x3d00070 1 >,
				<DCC_READ 0x3d000a0 4 0>,
				<DCC_READ 0x3d000b4 13 0>,
				<DCC_READ 0x3d00100 20 0>,
				<DCC_READ 0x3d00188 5 0>,
				<DCC_READ 0x3d001a4 6 0>,
				<DCC_READ 0x3d001c4 2 0>,
				<DCC_READ 0x3d001d0 1 >,
				<DCC_READ 0x3d001d8 2 0>,
				<DCC_READ 0x3d001fc 28 0>,
				<DCC_READ 0x3d00274 19 0>,
				<DCC_READ 0x3d002c8 35 0>,
				<DCC_READ 0x3d0035c 12 0>,
				<DCC_READ 0x3d00394 2 0>,
				<DCC_READ 0x3d003a4 9 0>,
				<DCC_READ 0x3d003d0 3 0>,
				<DCC_READ 0x3d003e4 16 0>,
				<DCC_READ 0x3d0042c 4 0>,
				<DCC_READ 0x3d00444 1 >,
				<DCC_READ 0x3d00450 9 0>,
				<DCC_READ 0x3d0047c 3 0>,
				<DCC_READ 0x3d00494 1 >,
				<DCC_READ 0x3d0049c 1 >,
				<DCC_READ 0x3d004a4 1 >,
				<DCC_READ 0x3d004ac 7 0>,
				<DCC_READ 0x3d004d0 5 0>,
				<DCC_READ 0x3d004e8 1 >,
				<DCC_READ 0x3d004f0 4 0>,
				<DCC_READ 0x3d00508 15 0>,
				<DCC_READ 0x3d0054c 3 0>,
				<DCC_READ 0x3d00560 2 0>,
				<DCC_READ 0x3d00570 1 >,
				<DCC_READ 0x3d00598 20 0>,
				<DCC_READ 0x3d00680 1 >,
				<DCC_READ 0x3d00f80 1 >,
				<DCC_READ 0x3d00fc0 1 >,
				<DCC_READ 0x3d01100 1 >,
				<DCC_READ 0x3d02000 31 0>,
				<DCC_READ 0x3d02080 4 0>,
				<DCC_READ 0x3d020d8 9 0>,
				<DCC_READ 0x3d02100 8 0>,
				<DCC_READ 0x3d0212c 5 0>,
				<DCC_READ 0x3d022c0 12 0>,
				<DCC_READ 0x3d02300 12 0>,
				<DCC_READ 0x3d0239c 5 0>,
				<DCC_READ 0x3d0f000 12 0>,
				<DCC_READ 0x3d0f100 3 0>,
				<DCC_READ 0x3d0f114 3 0>,
				<DCC_READ 0x3d0f124 6 0>,
				<DCC_READ 0x3d3c000 3 0>,
				<DCC_READ 0x3d3d000 1 >,
				<DCC_READ 0x3d3e000 4 0>,
				<DCC_READ 0x3d3f000 1 >,
				<DCC_READ 0x3d50000 21 0>,
				<DCC_READ 0x3d500d0 1 >,
				<DCC_READ 0x3d500d8 1 >,
				<DCC_READ 0x3d50100 3 0>,
				<DCC_READ 0x3d50110 2 0>,
				<DCC_READ 0x3d5011c 1 >,
				<DCC_READ 0x3d50200 5 0>,
				<DCC_READ 0x3d50400 5 0>,
				<DCC_READ 0x3d50450 1 >,
				<DCC_READ 0x3d50460 2 0>,
				<DCC_READ 0x3d50490 12 0>,
				<DCC_READ 0x3d50550 1 >,
				<DCC_READ 0x3d50d00 2 0>,
				<DCC_READ 0x3d50d10 1 >,
				<DCC_READ 0x3d50d18 13 0>,
				<DCC_READ 0x3d50fe0 1 >,
				<DCC_READ 0x3d50ff8 1 >,
				<DCC_READ 0x3d51010 1 >,
				<DCC_READ 0x3d51028 1 >,
				<DCC_READ 0x3d51280 1 >,
				<DCC_READ 0x3d51520 1 >,
				<DCC_READ 0x3d51538 1 >,
				<DCC_READ 0x3d51550 1 >,
				<DCC_READ 0x3d517c0 1 >,
				<DCC_READ 0x3d51a60 1 >,
				<DCC_READ 0x3d51a78 1 >,
				<DCC_READ 0x3d51a90 1 >,
				<DCC_READ 0x3d51aa8 1 >,
				<DCC_READ 0x3d51d00 1 >,
				<DCC_READ 0x3d51fa0 1 >,
				<DCC_READ 0x3d51fb8 1 >,
				<DCC_READ 0x3d52240 1 >,
				<DCC_READ 0x3d52258 1 >,
				<DCC_READ 0x3d524e0 1 >,
				<DCC_READ 0x3d64000 13 0>,
				<DCC_READ 0x3d6403c 1 >,
				<DCC_READ 0x3d66000 6 0>,
				<DCC_READ 0x3d67000 1 >,
				<DCC_READ 0x3d68000 5 0>,
				<DCC_READ 0x3d68020 11 0>,
				<DCC_READ 0x3d68050 1 >,
				<DCC_READ 0x3d6805c 1 >,
				<DCC_READ 0x3d68064 4 0>,
				<DCC_READ 0x3d68088 1 >,
				<DCC_READ 0x3d68090 6 0>,
				<DCC_READ 0x3d680fc 31 0>,
				<DCC_READ 0x3d68180 4 0>,
				<DCC_READ 0x3d68194 2 0>,
				<DCC_READ 0x3d681a0 15 0>,
				<DCC_READ 0x3d681e0 4 0>,
				<DCC_READ 0x3d69000 23 0>,
				<DCC_READ 0x3d69080 14 0>,
				<DCC_READ 0x3d690c0 2 0>,
				<DCC_READ 0x3d690d4 1 >,
				<DCC_READ 0x3d690dc 1 >,
				<DCC_READ 0x3d690e8 1 >,
				<DCC_READ 0x3d69108 1 >,
				<DCC_READ 0x3d69158 3 0>,
				<DCC_READ 0x3d6916c 3 0>,
				<DCC_READ 0x3d6917c 4 0>,
				<DCC_READ 0x3d7d000 12 0>,
				<DCC_READ 0x3d7d03c 3 0>,
				<DCC_READ 0x3d7d400 1 >,
				<DCC_READ 0x3d7d41c 1 >,
				<DCC_READ 0x3d7d424 3 0>,
				<DCC_READ 0x3d7dc58 1 >,
				<DCC_READ 0x3d7dc94 1 >,
				<DCC_READ 0x3d7dca4 1 >,
				<DCC_READ 0x3d7dd58 2 0>,
				<DCC_READ 0x3d7df80 2 0>,
				<DCC_READ 0x3d7df90 2 0>,
				<DCC_READ 0x3d7dfa0 2 0>,
				<DCC_READ 0x3d7dfb0 2 0>,
				<DCC_READ 0x3d7e000 5 0>,
				<DCC_READ 0x3d7e01c 2 0>,
				<DCC_READ 0x3d7e02c 2 0>,
				<DCC_READ 0x3d7e03c 1 >,
				<DCC_READ 0x3d7e044 1 >,
				<DCC_READ 0x3d7e04c 5 0>,
				<DCC_READ 0x3d7e064 4 0>,
				<DCC_READ 0x3d7e090 13 0>,
				<DCC_READ 0x3d7e100 2 0>,
				<DCC_READ 0x3d7e130 1 >,
				<DCC_READ 0x3d7e140 1 >,
				<DCC_READ 0x3d7e500 2 0>,
				<DCC_READ 0x3d7e50c 1 >,
				<DCC_READ 0x3d7e520 1 >,
				<DCC_READ 0x3d7e53c 1 >,
				<DCC_READ 0x3d7e550 2 0>,
				<DCC_READ 0x3d7e574 1 >,
				<DCC_READ 0x3d7e5c0 1 >,
				<DCC_READ 0x3d7e5f0 3 0>,
				<DCC_READ 0x3d7e600 2 0>,
				<DCC_READ 0x3d7e610 3 0>,
				<DCC_READ 0x3d7e648 2 0>,
				<DCC_READ 0x3d7e658 9 0>,
				<DCC_READ 0x3d7e700 16 0>,
				<DCC_READ 0x3d7e7c4 1 >,
				<DCC_READ 0x3d7e7e0 3 0>,
				<DCC_READ 0x3d7e7f0 1 >,
				<DCC_READ 0x3d7e800 4 0>,
				<DCC_READ 0x3d7f050 1 >,
				<DCC_READ 0x3d7f060 2 0>,
				<DCC_READ 0x3d7f080 1 >,
				<DCC_READ 0x3d7f090 3 0>,
				<DCC_READ 0x3d80080 1 >,
				<DCC_READ 0x3d800d0 3 0>,
				<DCC_READ 0x3d80c80 3 0>,
				<DCC_READ 0x3d80c90 3 0>,
				<DCC_READ 0x3d80ca0 3 0>,
				<DCC_READ 0x3d80d40 1 >,
				<DCC_READ 0x3d8e100 8 0>,
				<DCC_READ 0x3d8ec00 2 0>,
				<DCC_READ 0x3d8ec0c 1 >,
				<DCC_READ 0x3d8ec14 10 0>,
				<DCC_READ 0x3d8ec40 4 0>,
				<DCC_READ 0x3d8ec54 2 0>,
				<DCC_READ 0x3d8eca0 1 >,
				<DCC_READ 0x3d8ecc0 1 >,
				<DCC_READ 0x3d9200c 3 0>,
				<DCC_READ 0x3d93000 1 >,
				<DCC_READ 0x3d94000 3 0>,
				<DCC_READ 0x3d95000 5 0>,
				<DCC_READ 0x3d96000 5 0>,
				<DCC_READ 0x3d97000 5 0>,
				<DCC_READ 0x3d98000 5 0>,
				<DCC_READ 0x3d99000 7 0>,
				<DCC_READ 0x3d99054 4 0>,
				<DCC_READ 0x3d99070 2 0>,
				<DCC_READ 0x3d9907c 25 0>,
				<DCC_READ 0x3d990e4 2 0>,
				<DCC_READ 0x3d990f0 4 0>,
				<DCC_READ 0x3d9910c 2 0>,
				<DCC_READ 0x3d991e0 3 0>,
				<DCC_READ 0x3d99224 2 0>,
				<DCC_READ 0x3d99270 3 0>,
				<DCC_READ 0x3d99280 2 0>,
				<DCC_READ 0x3d99314 3 0>,
				<DCC_READ 0x3d993a0 3 0>,
				<DCC_READ 0x3d993e4 4 0>,
				<DCC_READ 0x3d9942c 1 >,
				<DCC_READ 0x3d99470 3 0>,
				<DCC_READ 0x3d99500 12 0>,
				<DCC_READ 0x3d99550 3 0>,
				<DCC_READ 0x3d99560 5 0>,
				<DCC_READ 0x3d99578 2 0>,
				<DCC_READ 0x3d9958c 1 >,
				<DCC_READ 0x3d995b4 7 0>,
				<DCC_READ 0x3d995d8 1 >,
				<DCC_READ 0x3d995e0 3 0>,
				<DCC_READ 0x3d9e000 1 >,
				<DCC_READ 0x3d9e040 5 0>,
				<DCC_READ 0x3d9e080 5 0>,
				<DCC_READ 0x3d9e0a0 3 0>,
				<DCC_READ 0x3d9e0c8 11 0>,
				<DCC_READ 0x3d9e0f8 26 0>,
				<DCC_READ 0x3d9e200 4 0>,
				<DCC_READ 0x3d9f000 2 0>,
				<DCC_READ 0x680030c 1 0>,
				<DCC_READ 0x68c0208 3 0>,
				<DCC_READ 0x68c0228 3 0>,
				<DCC_READ 0x68c0248 3 0>,
				<DCC_READ 0x68c0268 3 0>,
				<DCC_READ 0x68c0288 3 0>,
				<DCC_READ 0x68c02a8 3 0>,
				<DCC_READ 0x68c0404 2 0>,
				<DCC_READ 0x7200208 3 0>,
				<DCC_READ 0x7200228 3 0>,
				<DCC_READ 0x7200248 3 0>,
				<DCC_READ 0x7200268 3 0>,
				<DCC_READ 0x7200288 3 0>,
				<DCC_READ 0x72002a8 3 0>,
				<DCC_READ 0x257f0000 3 0>,
				<DCC_READ 0x257f0010 1 >,
				<DCC_READ 0x257f0018 1 >,
				<DCC_READ 0x257f0020 8 0>,
				<DCC_READ 0x257f0240 1 >,
				<DCC_READ 0x257f0248 1 >,
				<DCC_READ 0x257f2008 1 >,
				<DCC_LOOP 0x3 0 0>,
				<DCC_READ 0x257f2010 2 0>,
				<DCC_LOOP 0x1 0 0>,
				<DCC_READ 0x257f2018 1 0>,
				<DCC_READ 0x267f0008 1 >,
				<DCC_READ 0x267f0010 1 >,
				<DCC_READ 0x267f0018 1 >,
				<DCC_READ 0x267f0020 8 0>,
				<DCC_READ 0x267f0240 1 >,
				<DCC_READ 0x267f0248 1 >,
				<DCC_READ 0x267f2008 1 >,
				<DCC_LOOP 0x3 0 0>,
				<DCC_READ 0x267f2010 2 0>,
				<DCC_LOOP 0x1 0 0>,
				<DCC_READ 0x267f2018 1 0>,
				<DCC_READ 0x17421000 2 0>;
		};
	};

	mem_dump {
		compatible = "qcom,mem-dump";
		memory-region = <&dump_mem>;

		static_dump {
			qcom,static-mem-dump;

			c0_context {
				qcom,dump-size = <0x800>;
				qcom,dump-id = <0x0>;
			};

			c100_context {
				qcom,dump-size = <0x800>;
				qcom,dump-id = <0x1>;
			};

			c200_context {
				qcom,dump-size = <0x800>;
				qcom,dump-id = <0x2>;
			};

			c300_context {
				qcom,dump-size = <0x800>;
				qcom,dump-id = <0x3>;
			};

			c400_context {
				qcom,dump-size = <0x800>;
				qcom,dump-id = <0x4>;
			};

			c500_context {
				qcom,dump-size = <0x800>;
				qcom,dump-id = <0x5>;
			};

			c600_context {
				qcom,dump-size = <0x800>;
				qcom,dump-id = <0x6>;
			};

			c700_context {
				qcom,dump-size = <0x800>;
				qcom,dump-id = <0x7>;
			};

			l1_icache0 {
				qcom,dump-size = <0x22100>;
				qcom,dump-id = <0x60>;
			};

			l1_icache100 {
				qcom,dump-size = <0x22100>;
				qcom,dump-id = <0x61>;
			};

			l1_icache200 {
				qcom,dump-size = <0x22100>;
				qcom,dump-id = <0x62>;
			};

			l1_icache300 {
				qcom,dump-size = <0x22100>;
				qcom,dump-id = <0x63>;
			};

			l1_icache400 {
				qcom,dump-size = <0x22100>;
				qcom,dump-id = <0x64>;
			};

			l1_icache500 {
				qcom,dump-size = <0x22100>;
				qcom,dump-id = <0x65>;
			};

			l1_icache600 {
				qcom,dump-size = <0x22100>;
				qcom,dump-id = <0x66>;
			};

			l1_icache700 {
				qcom,dump-size = <0x22100>;
				qcom,dump-id = <0x67>;
			};

			l1_dcache0 {
				qcom,dump-size = <0x12100>;
				qcom,dump-id = <0x80>;
			};

			l1_dcache100 {
				qcom,dump-size = <0x12100>;
				qcom,dump-id = <0x81>;
			};

			l1_dcache200 {
				qcom,dump-size = <0x1a100>;
				qcom,dump-id = <0x82>;
			};

			l1_dcache300 {
				qcom,dump-size = <0x1a100>;
				qcom,dump-id = <0x83>;
			};

			l1_dcache400 {
				qcom,dump-size = <0x1a100>;
				qcom,dump-id = <0x84>;
			};

			l1_dcache500 {
				qcom,dump-size = <0x1a100>;
				qcom,dump-id = <0x85>;
			};

			l1_dcache600 {
				qcom,dump-size = <0x1a100>;
				qcom,dump-id = <0x86>;
			};

			l1_dcache700 {
				qcom,dump-size = <0x1a100>;
				qcom,dump-id = <0x87>;
			};

			l1_itlb700 {
				qcom,dump-size = <0x600>;
				qcom,dump-id = <0x27>;
			};

			l1_dtlb700 {
				qcom,dump-size = <0xa00>;
				qcom,dump-id = <0x47>;
			};

			l2_cache0 {
				qcom,dump-size = <0x90100>;
				qcom,dump-id = <0xc0>;
			};

			l2_cache100 {
				qcom,dump-size = <0x90100>;
				qcom,dump-id = <0xc1>;
			};

			l2_cache200 {
				qcom,dump-size = <0xd0100>;
				qcom,dump-id = <0xc2>;
			};

			l2_cache300 {
				qcom,dump-size = <0xd0100>;
				qcom,dump-id = <0xc3>;
			};

			l2_cache400 {
				qcom,dump-size = <0xd0100>;
				qcom,dump-id = <0xc4>;
			};

			l2_cache500 {
				qcom,dump-size = <0xd0100>;
				qcom,dump-id = <0xc5>;
			};

			l2_cache600 {
				qcom,dump-size = <0xd0100>;
				qcom,dump-id = <0xc6>;
			};

			l2_cache700 {
				qcom,dump-size = <0x340100>;
				qcom,dump-id = <0xc7>;
			};

			l2_tlb0 {
				qcom,dump-size = <0xf700>;
				qcom,dump-id = <0x120>;
			};

			l2_tlb100 {
				qcom,dump-size = <0xf700>;
				qcom,dump-id = <0x121>;
			};

			l2_tlb700 {
				qcom,dump-size = <0xa900>;
				qcom,dump-id = <0x127>;
			};

			l1dcdirty0 {
				qcom,dump-size = <0x2100>;
				qcom,dump-id = <0x170>;
			};

			l1dcdirty100 {
				qcom,dump-size = <0x2100>;
				qcom,dump-id = <0x171>;
			};

			l1dcmte0 {
				qcom,dump-size = <0x2100>;
				qcom,dump-id = <0x180>;
			};

			l1dcmte100 {
				qcom,dump-size = <0x2100>;
				qcom,dump-id = <0x181>;
			};

			l2dcmte0 {
				qcom,dump-size = <0x10100>;
				qcom,dump-id = <0x190>;
			};

			l2dcmte100 {
				qcom,dump-size = <0x10100>;
				qcom,dump-id = <0x191>;
			};

			l0mopca700 {
				qcom,dump-size = <0x4100>;
				qcom,dump-id = <0x1a7>;
			};

			l2victim700 {
				qcom,dump-size = <0x2100>;
				qcom,dump-id = <0x1e7>;
			};

			l2tldtcsp200 {
				qcom,dump-size = <0x7900>;
				qcom,dump-id = <0x202>;
			};

			l2tldtcsp300 {
				qcom,dump-size = <0x7900>;
				qcom,dump-id = <0x203>;
			};

			l2tldtcsp400 {
				qcom,dump-size = <0x7900>;
				qcom,dump-id = <0x204>;
			};

			l2tldtcsp500 {
				qcom,dump-size = <0x7900>;
				qcom,dump-id = <0x205>;
			};

			l2tldtcsp600 {
				qcom,dump-size = <0x7900>;
				qcom,dump-id = <0x206>;
			};

			l2tldtcmp200 {
				qcom,dump-size = <0x1300>;
				qcom,dump-id = <0x212>;
			};

			l2tldtcmp300 {
				qcom,dump-size = <0x1300>;
				qcom,dump-id = <0x213>;
			};

			l2tldtcmp400 {
				qcom,dump-size = <0x1300>;
				qcom,dump-id = <0x214>;
			};

			l2tldtcmp500 {
				qcom,dump-size = <0x1300>;
				qcom,dump-id = <0x215>;
			};

			l2tldtcmp600 {
				qcom,dump-size = <0x1300>;
				qcom,dump-id = <0x216>;
			};

			rpmh {
				qcom,dump-size = <0x400000>;
				qcom,dump-id = <0xec>;
			};

			rpm_sw {
				qcom,dump-size = <0x28000>;
				qcom,dump-id = <0xea>;
			};

			pmic {
				qcom,dump-size = <0x200000>;
				qcom,dump-id = <0xe4>;
			};

			fcm {
				qcom,dump-size = <0x8400>;
				qcom,dump-id = <0xee>;
			};

			etf_swao {
				qcom,dump-size = <0x10000>;
				qcom,dump-id = <0xf1>;
			};

			etr_reg {
				qcom,dump-size = <0x1000>;
				qcom,dump-id = <0x100>;
			};

			etfswao_reg {
				qcom,dump-size = <0x1000>;
				qcom,dump-id = <0x102>;
			};

			etr1_reg {
				qcom,dump-size = <0x1000>;
				qcom,dump-id = <0x105>;
			};

			misc_data {
				qcom,dump-size = <0x1000>;
				qcom,dump-id = <0xe8>;
			};

			etf_slpi {
				qcom,dump-size = <0x4000>;
				qcom,dump-id = <0xf3>;
			};

			etfslpi_reg {
				qcom,dump-size = <0x1000>;
				qcom,dump-id = <0x103>;
			};

			etf_lpass {
				qcom,dump-size = <0x4000>;
				qcom,dump-id = <0xf4>;
			};

			etflpass_reg {
				qcom,dump-size = <0x1000>;
				qcom,dump-id = <0x104>;
			};

			osm_reg {
				qcom,dump-size = <0x400>;
				qcom,dump-id = <0x163>;
			};

			pcu_reg {
				qcom,dump-size = <0x400>;
				qcom,dump-id = <0x164>;
			};

			fsm_data {
				qcom,dump-size = <0x400>;
				qcom,dump-id = <0x165>;
			};

			scandump_smmu {
				qcom,dump-size = <0x40000>;
				qcom,dump-id = <0x220>;
			};
		};

		dynamic_mem_dump {
			qcom,dynamic-mem-dump;

			scandump_gpu {
				scandump_gpu {
					qcom,dump-size = <0x300000>;
					qcom,dump-id = <0x221>;
				};
			};

			cpuss_reg {
				cpuss_reg {
					qcom,dump-size = <0x36000>;
					qcom,dump-id = <0xef>;
				};
			};

			spr {
				spr_cpu0 {
					qcom,dump-size = <0x2000>;
					qcom,dump-id = <0x1f0>;
				};

				spr_cpu1 {
					qcom,dump-size = <0x2000>;
					qcom,dump-id = <0x1f1>;
				};

				spr_cpu2 {
					qcom,dump-size = <0x2000>;
					qcom,dump-id = <0x1f2>;
				};

				spr_cpu3 {
					qcom,dump-size = <0x2000>;
					qcom,dump-id = <0x1f3>;
				};

				spr_cpu4 {
					qcom,dump-size = <0x2000>;
					qcom,dump-id = <0x1f4>;
				};

				spr_cpu5 {
					qcom,dump-size = <0x2000>;
					qcom,dump-id = <0x1f5>;
				};

				spr_cpu6 {
					qcom,dump-size = <0x2000>;
					qcom,dump-id = <0x1f6>;
				};

				spr_cpu7 {
					qcom,dump-size = <0x2000>;
					qcom,dump-id = <0x1f7>;
				};
			};
		};
	};
};

